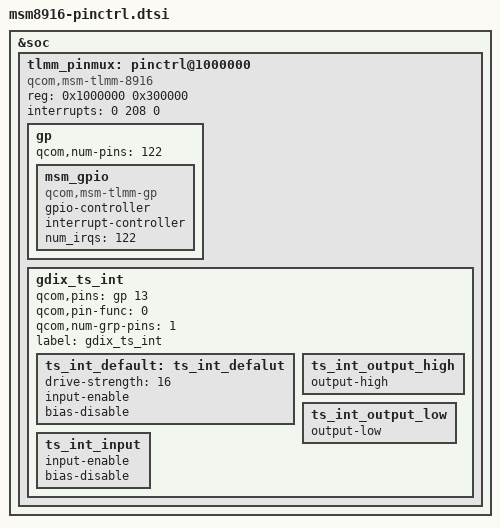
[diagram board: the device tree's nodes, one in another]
/* Copyright (c) 2013-2015, The Linux Foundation. All rights reserved.
 *
 * This program is free software; you can redistribute it and/or modify
 * it under the terms of the GNU General Public License version 2 and
 * only version 2 as published by the Free Software Foundation.
 *
 * This program is distributed in the hope that it will be useful,
 * but WITHOUT ANY WARRANTY; without even the implied warranty of
 * MERCHANTABILITY or FITNESS FOR A PARTICULAR PURPOSE.  See the
 * GNU General Public License for more details.
 */

&soc {
	tlmm_pinmux: pinctrl@1000000 {
		compatible = "qcom,msm-tlmm-8916";
		reg = <0x1000000 0x300000>;
		interrupts = <0 208 0>;

		/*General purpose pins*/
		gp: gp {
			qcom,num-pins = <122>;
			#qcom,pin-cells = <1>;
			msm_gpio: msm_gpio {
				compatible = "qcom,msm-tlmm-gp";
				gpio-controller;
				#gpio-cells = <2>;
				interrupt-controller;
				#interrupt-cells = <2>;
				num_irqs = <122>;
			};
		};

		/* add pingrp for touchscreen */

		gdix_ts_int {
			qcom,pins = <&gp 13>;
			qcom,pin-func = <0>;
			qcom,num-grp-pins = <1>;
			label = "gdix_ts_int";

			ts_int_default: ts_int_defalut {
				drive-strength = <16>;
				/*bias-pull-up;*/
				input-enable;
				bias-disable;
			};

			ts_int_output_high: ts_int_output_high {
				output-high;
			};

			ts_int_output_low: ts_int_output_low {
			   output-low;
			};

			ts_int_input: ts_int_input {
				input-enable;
				bias-disable;
			};
		};


	};
};
